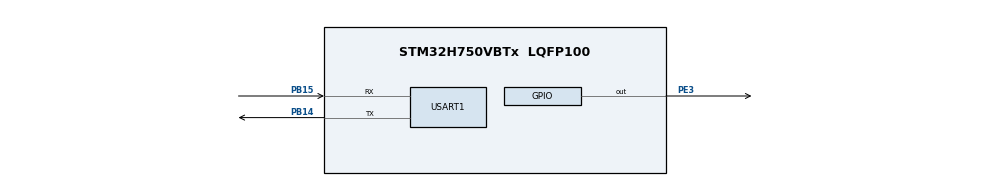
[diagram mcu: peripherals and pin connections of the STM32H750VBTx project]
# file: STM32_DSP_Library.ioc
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Mcu.Family=STM32H7
Mcu.Name=STM32H750VBTx
Mcu.Package=LQFP100
NVIC.PriorityGroup=NVIC_PRIORITYGROUP_4
PA13\ (JTMS/SWDIO).Mode=Serial_Wire
PA13\ (JTMS/SWDIO).Signal=DEBUG_JTMS-SWDIO
PA14\ (JTCK/SWCLK).Mode=Serial_Wire
PA14\ (JTCK/SWCLK).Signal=DEBUG_JTCK-SWCLK
PB14.Mode=Asynchronous
PB14.Signal=USART1_TX
PB15.Mode=Asynchronous
PB15.Signal=USART1_RX
PE3.Signal=GPIO_Output
PH0-OSC_IN\ (PH0).Mode=HSE-External-Oscillator
PH0-OSC_IN\ (PH0).Signal=RCC_OSC_IN
PH1-OSC_OUT\ (PH1).Mode=HSE-External-Oscillator
PH1-OSC_OUT\ (PH1).Signal=RCC_OSC_OUT
ProjectManager.HeapSize=0x200
ProjectManager.StackSize=0x400
ProjectManager.TargetToolchain=STM32CubeIDE
RCC.ADCFreq_Value=50390625
RCC.APB1Freq_Value=75000000
RCC.APB2Freq_Value=37500000
RCC.APB3Freq_Value=75000000
RCC.APB4Freq_Value=75000000
RCC.CortexFreq_Value=75000000
RCC.D2PPRE2=RCC_APB2_DIV2
RCC.DIVM1=2
RCC.DIVN1=12
RCC.HCLKFreq_Value=75000000
RCC.PLLFRACN=0
RCC.PLLSourceVirtual=RCC_PLLSOURCE_HSE
RCC.SYSCLKFreq_VALUE=75000000
RCC.SYSCLKSource=RCC_SYSCLKSOURCE_PLLCLK
RCC.USBFreq_Value=75000000
USART1.VirtualMode-Asynchronous=VM_ASYNC
board=custom

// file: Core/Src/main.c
/* USER CODE BEGIN Header */
/**
  ******************************************************************************
  * @file           : main.c
  * @brief          : Main program body
  ******************************************************************************
  * @attention
  *
  * Copyright (c) 2023 STMicroelectronics.
  * All rights reserved.
  *
  * This software is licensed under terms that can be found in the LICENSE file
  * in the root directory of this software component.
  * If no LICENSE file comes with this software, it is provided AS-IS.
  *
  ******************************************************************************
  */
/* USER CODE END Header */
#include "main.h"
#include "usart.h"
#include "gpio.h"

/* USER CODE BEGIN Includes */
#include "arm_math.h"
#include "FFTInc.h"
/* USER CODE END Includes */

void SystemClock_Config(void);

int main(void)
{

  /* MCU Configuration--------------------------------------------------------*/

  /* Reset of all peripherals, Initializes the Flash interface and the Systick. */
  HAL_Init();

  /* Configure the system clock */
  SystemClock_Config();

  /* Initialize all configured peripherals */
  MX_GPIO_Init();
  MX_USART1_UART_Init();
  /* USER CODE BEGIN 2 */
  struct compx fft[8192] = { 1 };
  cfft(fft, 8192);
  q31_t count = 0;
  /* USER CODE END 2 */

  /* Infinite loop */
  while (1)
  {

    /* USER CODE BEGIN 3 */
    HAL_GPIO_WritePin(GPIOE, GPIO_PIN_3, arm_cos_f32(PI/ 2 * (float32_t)((count ++ ) % 2)));
    HAL_Delay(200);
    if (count > 255) count = 0;
  }
  /* USER CODE END 3 */
}

void SystemClock_Config(void)
{
  RCC_OscInitTypeDef RCC_OscInitStruct = {0};
  RCC_ClkInitTypeDef RCC_ClkInitStruct = {0};

  /** Supply configuration update enable
  */
  HAL_PWREx_ConfigSupply(PWR_LDO_SUPPLY);

  /** Configure the main internal regulator output voltage
  */
  __HAL_PWR_VOLTAGESCALING_CONFIG(PWR_REGULATOR_VOLTAGE_SCALE3);

  while(!__HAL_PWR_GET_FLAG(PWR_FLAG_VOSRDY)) {}

  /** Initializes the RCC Oscillators according to the specified parameters
  * in the RCC_OscInitTypeDef structure.
  */
  RCC_OscInitStruct.OscillatorType = RCC_OSCILLATORTYPE_HSE;
  RCC_OscInitStruct.HSEState = RCC_HSE_ON;
  RCC_OscInitStruct.PLL.PLLState = RCC_PLL_ON;
  RCC_OscInitStruct.PLL.PLLSource = RCC_PLLSOURCE_HSE;
  RCC_OscInitStruct.PLL.PLLM = 2;
  RCC_OscInitStruct.PLL.PLLN = 12;
  RCC_OscInitStruct.PLL.PLLP = 2;
  RCC_OscInitStruct.PLL.PLLQ = 2;
  RCC_OscInitStruct.PLL.PLLR = 2;
  RCC_OscInitStruct.PLL.PLLRGE = RCC_PLL1VCIRANGE_3;
  RCC_OscInitStruct.PLL.PLLVCOSEL = RCC_PLL1VCOMEDIUM;
  RCC_OscInitStruct.PLL.PLLFRACN = 0;
  if (HAL_RCC_OscConfig(&RCC_OscInitStruct) != HAL_OK)
  {
    Error_Handler();
  }

  /** Initializes the CPU, AHB and APB buses clocks
  */
  RCC_ClkInitStruct.ClockType = RCC_CLOCKTYPE_HCLK|RCC_CLOCKTYPE_SYSCLK
                              |RCC_CLOCKTYPE_PCLK1|RCC_CLOCKTYPE_PCLK2
                              |RCC_CLOCKTYPE_D3PCLK1|RCC_CLOCKTYPE_D1PCLK1;
  RCC_ClkInitStruct.SYSCLKSource = RCC_SYSCLKSOURCE_PLLCLK;
  RCC_ClkInitStruct.SYSCLKDivider = RCC_SYSCLK_DIV1;
  RCC_ClkInitStruct.AHBCLKDivider = RCC_HCLK_DIV1;
  RCC_ClkInitStruct.APB3CLKDivider = RCC_APB3_DIV1;
  RCC_ClkInitStruct.APB1CLKDivider = RCC_APB1_DIV1;
  RCC_ClkInitStruct.APB2CLKDivider = RCC_APB2_DIV2;
  RCC_ClkInitStruct.APB4CLKDivider = RCC_APB4_DIV1;

  if (HAL_RCC_ClockConfig(&RCC_ClkInitStruct, FLASH_LATENCY_1) != HAL_OK)
  {
    Error_Handler();
  }
}

void Error_Handler(void)
{
  __disable_irq();
  while (1)
  {
  }
}
